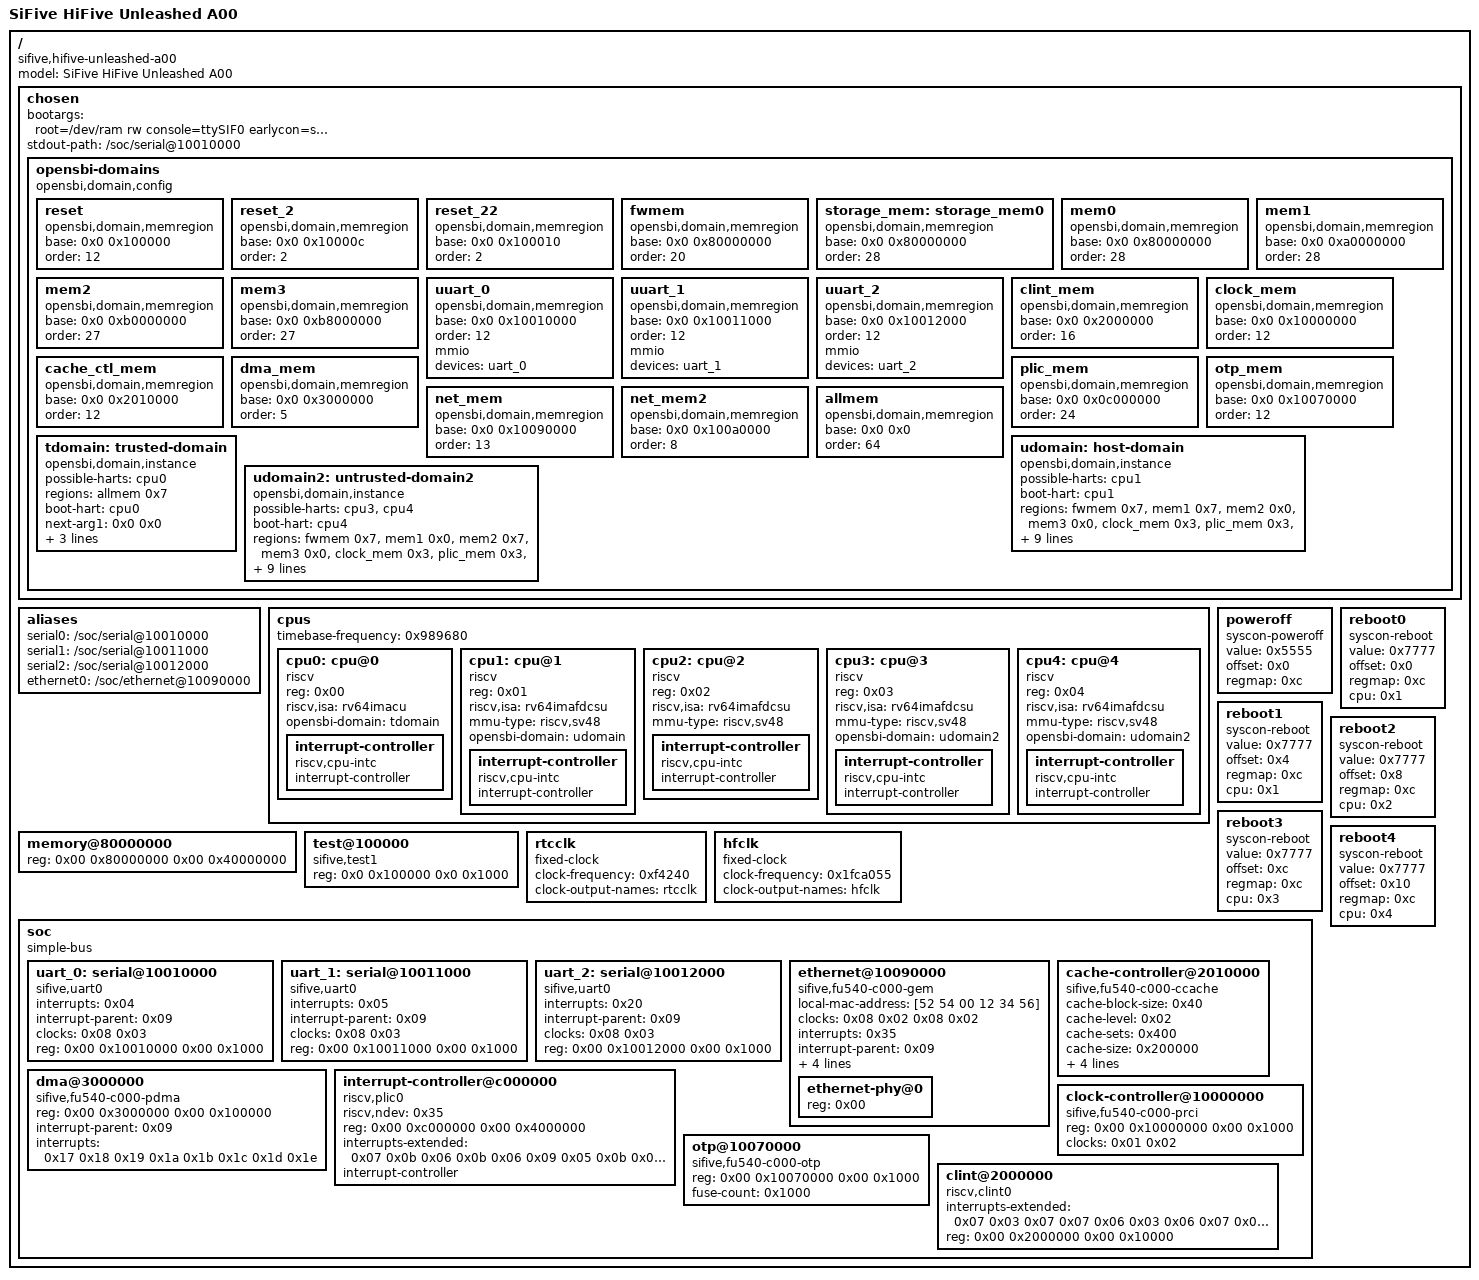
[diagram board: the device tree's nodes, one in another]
/dts-v1/;

/ {
	#address-cells = <0x02>;
	#size-cells = <0x02>;
	compatible = "sifive,hifive-unleashed-a00";
	model = "SiFive HiFive Unleashed A00";

	chosen {
		bootargs = "root=/dev/ram rw console=ttySIF0 earlycon=sbi";
		stdout-path = "/soc/serial@10010000";

		opensbi-domains {
			compatible = "opensbi,domain,config";
			reset: reset {
				compatible = "opensbi,domain,memregion";
				base = <0x0 0x100000>;
				order = <12>;
			};

			reset_2: reset_2 {
				compatible = "opensbi,domain,memregion";
				base = <0x0 0x10000c>;
				order = <2>;
			};
			reset_22: reset_22 {
				compatible = "opensbi,domain,memregion";
				base = <0x0 0x100010>;
				order = <2>;
			};

			fwmem: fwmem {
				compatible = "opensbi,domain,memregion";
				base = <0x0 0x80000000>;
				order = <20>;
			};

			storage_mem: storage_mem0 {
				compatible = "opensbi,domain,memregion";
				base = <0x0 0x80000000>;
				order = <28>;
			};

			mem0: mem0 {
				compatible = "opensbi,domain,memregion";
				base = <0x0 0x80000000>;
				order = <28>;
			};

			mem1: mem1 {
				compatible = "opensbi,domain,memregion";
				base = <0x0 0xa0000000>;
				order = <28>;
			};

			mem2: mem2 {
				compatible = "opensbi,domain,memregion";
				base = <0x0 0xb0000000>;
				order = <27>;
			};

			mem3: mem3 {
				compatible = "opensbi,domain,memregion";
				base = <0x0 0xb8000000>;
				order = <27>;
			};

			uuart_0: uuart_0 {
				compatible = "opensbi,domain,memregion";
				base = <0x0 0x10010000>;
				order = <12>;
				mmio;
				devices = <&uart_0>;
			};

			uuart_1: uuart_1 {
				compatible = "opensbi,domain,memregion";
				base = <0x0 0x10011000>;
				order = <12>;
				mmio;
				devices = <&uart_1>;
			};

			uuart_2: uuart_2 {
				compatible = "opensbi,domain,memregion";
				base = <0x0 0x10012000>;
				order = <12>;
				mmio;
				devices = <&uart_2>;
			};

			clint_mem: clint_mem {
				compatible = "opensbi,domain,memregion";
				base = <0x0 0x2000000>;
				order = <16>;
			};
			clock_mem: clock_mem {
				compatible = "opensbi,domain,memregion";
				base = <0x0 0x10000000>;
				order = <12>;
			};
			cache_ctl_mem:cache_ctl_mem {
				compatible = "opensbi,domain,memregion";
				base = <0x0 0x2010000>;
				order = <12>;
			};
			dma_mem:dma_mem {
				compatible = "opensbi,domain,memregion";
				base = <0x0 0x3000000>;
				order=<5>;
			};
			plic_mem: plic_mem {
				compatible = "opensbi,domain,memregion";
				base = <0x0 0x0c000000>;
				order = <24>;
			};
			otp_mem:otp_mem {
				compatible = "opensbi,domain,memregion";
				base = <0x0 0x10070000>;
				order = <12>;
			};
			net_mem:net_mem {
				compatible = "opensbi,domain,memregion";
				base = <0x0 0x10090000>;
				order = <13>;
			};
			net_mem2:net_mem2 {
				compatible = "opensbi,domain,memregion";
				base = <0x0 0x100a0000>;
				order = <8>;
			};

			allmem: allmem {
				compatible = "opensbi,domain,memregion";
				base = <0x0 0x0>;
				order = <64>;
			};

			tdomain: trusted-domain {
				compatible = "opensbi,domain,instance";
				possible-harts = <&cpu0>;
				regions = <&allmem 0x7>;
				boot-hart = <&cpu0>;
				next-arg1 = <0x0 0x0>;
				next-addr = <0x0 0x80100000>;
				next-mode = <0x1>;
				system-reset-allowed;
				//stdout-path = "/soc/serial@10010000";
			};

			udomain: host-domain {
				compatible = "opensbi,domain,instance";
				possible-harts = <&cpu1>;
				boot-hart = <&cpu1>;
				regions =  <&fwmem 0x7>, <&mem1 0x7>, <&mem2 0x0>, <&mem3 0x0>, <&clock_mem 0x3>, <&plic_mem 0x3>,<&net_mem 0x3>, <&uuart_1 0x7>, <&reset 0x7>, <&allmem 0x0>;
				next-arg1 = <0x0 0xa2200000>;
				next-addr = <0x0 0xa0200000>;
				next-mode = <0x1>;
				system-reset-allowed;
				stdout-path = "/soc/serial@10011000";
				next-boot-src =  <0x0 0x80200000>;
				// could be replace with your Image size.
				// Used 0x2000000 as a default value for any kernel image;
				next-boot-size = <0x0 0x02000000>;
			};

			udomain2: untrusted-domain2 {
				compatible = "opensbi,domain,instance";
				possible-harts = <&cpu3 &cpu4>;
				boot-hart = <&cpu4>;
				regions = <&fwmem 0x7>, <&mem1 0x0>, <&mem2 0x7>, <&mem3 0x0>, <&clock_mem 0x3>, <&plic_mem 0x3>, <&net_mem 0x3>, <&uuart_2 0x3>, <&reset_2 0x7>, <&reset_22 0x7>, <&reset 0x8>, <&allmem 0x0>;
				next-arg1 = <0x0 0xb2200000>;
				next-addr = <0x0 0xb0200000>;
				next-mode = <0x1>;
				system-reset-allowed;
				stdout-path = "/soc/serial@10012000";
				next-boot-src =  <0x0 0x84000000>;
				// could be replace with your Image size
				// Used 0x2000000 as a default value for any kernel image;
				next-boot-size = <0x0 0x02000000>;
			};

		};
	};

	aliases {
		serial0 = "/soc/serial@10010000";
		serial1 = "/soc/serial@10011000";
		serial2 = "/soc/serial@10012000";
		ethernet0 = "/soc/ethernet@10090000";
	};

	cpus {
		#address-cells = <0x01>;
		#size-cells = <0x00>;
		timebase-frequency = <0x989680>;

		cpu0: cpu@0 {
			device_type = "cpu";
			reg = <0x00>;
			status = "okay";
			compatible = "riscv";
			riscv,isa = "rv64imacu";
			opensbi-domain = <&tdomain>;

			interrupt-controller {
				#interrupt-cells = <0x01>;
				interrupt-controller;
				compatible = "riscv,cpu-intc";
				phandle = <0x07>;
			};
		};

		cpu1: cpu@1 {
			device_type = "cpu";
			reg = <0x01>;
			status = "okay";
			compatible = "riscv";
			riscv,isa = "rv64imafdcsu";
			mmu-type = "riscv,sv48";
			opensbi-domain = <&udomain>;

			interrupt-controller {
				#interrupt-cells = <0x01>;
				interrupt-controller;
				compatible = "riscv,cpu-intc";
				phandle = <0x06>;
			};
		};

		cpu2: cpu@2 {
			device_type = "cpu";
			reg = <0x02>;
			status = "okay";
			compatible = "riscv";
			riscv,isa = "rv64imafdcsu";
			mmu-type = "riscv,sv48";
			
			interrupt-controller {
				#interrupt-cells = <0x01>;
				interrupt-controller;
				compatible = "riscv,cpu-intc";
				phandle = <0x05>;
			};
		};

		cpu3: cpu@3 {
			device_type = "cpu";
			reg = <0x03>;
			status = "okay";
			compatible = "riscv";
			riscv,isa = "rv64imafdcsu";
			mmu-type = "riscv,sv48";
			opensbi-domain = <&udomain2>;

			interrupt-controller {
				#interrupt-cells = <0x01>;
				interrupt-controller;
				compatible = "riscv,cpu-intc";
				phandle = <0x04>;
			};
		};

		cpu4: cpu@4 {
			device_type = "cpu";
			reg = <0x04>;
			status = "okay";
			compatible = "riscv";
			riscv,isa = "rv64imafdcsu";
			mmu-type = "riscv,sv48";
			opensbi-domain = <&udomain2>;

			interrupt-controller {
				#interrupt-cells = <0x01>;
				interrupt-controller;
				compatible = "riscv,cpu-intc";
				phandle = <0x03>;
			};
		};
	};

	memory@80000000 {
		device_type = "memory";
		reg = <0x00 0x80000000 0x00 0x40000000>;
	};

	poweroff {
		value = <0x5555>;
		offset = <0x0>;
		regmap = <0xc>;
		compatible = "syscon-poweroff";
	};

	reboot0 {
		value = <0x7777>;
		offset = <0x0>;
		regmap = <0xc>;
		compatible = "syscon-reboot";
		cpu = <0x1>;
	};

	reboot1 {
		value = <0x7777>;
		offset = <0x4>;
		regmap = <0xc>;
		compatible = "syscon-reboot";
		cpu = <0x1>;
	};

	reboot2 {
		value = <0x7777>;
		offset = <0x8>;
		regmap = <0xc>;
		compatible = "syscon-reboot";
		cpu = <0x2>;
	};

	reboot3 {
		value = <0x7777>;
		offset = <0xc>;
		regmap = <0xc>;
		compatible = "syscon-reboot";
		cpu = <0x3>;
	};

	reboot4 {
		value = <0x7777>;
		offset = <0x10>;
		regmap = <0xc>;
		compatible = "syscon-reboot";
		cpu = <0x4>;
	};

	test@100000 {
		phandle = <0xc>;
		reg = <0x0 0x100000 0x0 0x1000>;
		compatible = "sifive,test1", "sifive,test0", "syscon", "domain-reset";
	};

	rtcclk {
		#clock-cells = <0x00>;
		compatible = "fixed-clock";
		clock-frequency = <0xf4240>;
		clock-output-names = "rtcclk";
		phandle = <0x02>;
	};

	hfclk {
		#clock-cells = <0x00>;
		compatible = "fixed-clock";
		clock-frequency = <0x1fca055>;
		clock-output-names = "hfclk";
		phandle = <0x01>;
	};

	soc {
		#address-cells = <0x02>;
		#size-cells = <0x02>;
		compatible = "simple-bus";
		ranges;

		uart_0: serial@10010000 {
			interrupts = <0x04>;
			interrupt-parent = <0x09>;
			clocks = <0x08 0x03>;
			reg = <0x00 0x10010000 0x00 0x1000>;
			compatible = "sifive,uart0";
		};

		uart_1: serial@10011000 {
			interrupts = <0x05>;
			interrupt-parent = <0x09>;
			clocks = <0x08 0x03>;
			reg = <0x00 0x10011000 0x00 0x1000>;
			compatible = "sifive,uart0";
		};

		uart_2: serial@10012000 {
			interrupts = <0x20>;
			interrupt-parent = <0x09>;
			clocks = <0x08 0x03>;
			reg = <0x00 0x10012000 0x00 0x1000>;
			compatible = "sifive,uart0";
		};

		ethernet@10090000 {
			#size-cells = <0x00>;
			#address-cells = <0x01>;
			local-mac-address = [52 54 00 12 34 56];
			clock-names = "pclk\0hclk";
			clocks = <0x08 0x02 0x08 0x02>;
			interrupts = <0x35>;
			interrupt-parent = <0x09>;
			phy-handle = <0x0b>;
			phy-mode = "gmii";
			reg-names = "control";
			reg = <0x00 0x10090000 0x00 0x2000 0x00 0x100a0000 0x00 0x1000>;
			compatible = "sifive,fu540-c000-gem";

			ethernet-phy@0 {
				reg = <0x00>;
				phandle = <0x0b>;
			};
		};

		cache-controller@2010000 {
			compatible = "sifive,fu540-c000-ccache";
			cache-block-size = <0x40>;
			cache-level = <0x02>;
			cache-sets = <0x400>;
			cache-size = <0x200000>;
			cache-unified;
			interrupt-parent = <0x09>;
			interrupts = <0x01 0x02 0x03>;
			reg = <0x00 0x2010000 0x00 0x1000>;
		};

		dma@3000000 {
			compatible = "sifive,fu540-c000-pdma";
			reg = <0x00 0x3000000 0x00 0x100000>;
			interrupt-parent = <0x09>;
			interrupts = <0x17 0x18 0x19 0x1a 0x1b 0x1c 0x1d 0x1e>;
			#dma-cells = <0x01>;
		};

		interrupt-controller@c000000 {
			phandle = <0x09>;
			riscv,ndev = <0x35>;
			reg = <0x00 0xc000000 0x00 0x4000000>;
			interrupts-extended = <0x07 0x0b 0x06 0x0b 0x06 0x09 0x05 0x0b 0x05 0x09 0x04 0x0b 0x04 0x09 0x03 0x0b 0x03 0x09>;
			interrupt-controller;
			compatible = "riscv,plic0";
			#interrupt-cells = <0x01>;
		};

		clock-controller@10000000 {
			compatible = "sifive,fu540-c000-prci";
			reg = <0x00 0x10000000 0x00 0x1000>;
			clocks = <0x01 0x02>;
			#clock-cells = <0x01>;
			phandle = <0x08>;
		};

		
		otp@10070000 {
			compatible = "sifive,fu540-c000-otp";
			reg = <0x00 0x10070000 0x00 0x1000>;
			fuse-count = <0x1000>;
		};

		// fdt_parse_clint_node.
		// lib/utils/sys/clint.c includes hardcoded offset for per-cpu msip, per-cpu timecmp, and shared time.
		clint@2000000 {
			//sbi/riscv_encoding.h cpu0 soft cpu0 time cpu1 soft cpu1 time cpu2 soft cpu2 time ...
			interrupts-extended = <0x07 0x03 0x07 0x07 0x06 0x03 0x06 0x07 0x05 0x03 0x05 0x07 0x04 0x03 0x04 0x07 0x03 0x03 0x03 0x07>;
			reg = <0x00 0x2000000 0x00 0x10000>;
			compatible = "riscv,clint0";
		};
	};
};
